# ESP32C5_RADIO register map
Vendor: Espressif; Series: ESP32-C5; File version: 0.1
Registers are 32-bit, read-write, no defined reset value unless marked. A register's access mark holds for its fields unless they carry their own. Offsets are from the block's base; [hi:lo] are bit positions; 'fields as' and 'values as' point back to an identical list.

## LP_CLKRST_RESET_CAUSE — Low-power clock/reset registers: the reset cause of the HP core. Firmware reads it after boot; the host reads it through JTAG after a power cycle.
Base 0x600B0400
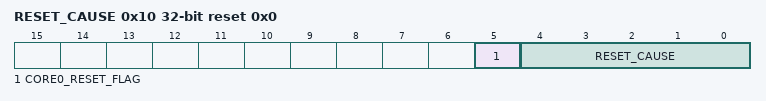
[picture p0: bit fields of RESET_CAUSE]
0x10 RESET_CAUSE ro reset 0x0 — Why the HP core last left reset. It holds until the next reset, so a host reads it through JTAG after the core returned.
  [5] CORE0_RESET_FLAG — Set when the HP core left reset.
  [4:0] RESET_CAUSE — The reset cause code: one is a power-on reset; others are system, watchdog, brown-out, USB Serial/JTAG and JTAG resets.

## USB_SERIAL_JTAG — USB Serial/JTAG controller: the CDC-ACM data FIFO, its configuration and the two interrupts of the serial endpoints. The JTAG side and the other interrupt sources are not described.
Base 0x6000F000
0x00 EP1 reset 0x0 — FIFO access for the CDC-ACM data IN and OUT endpoints: a write appends a byte to the IN FIFO, a read takes one from the OUT FIFO.
  [7:0] RDWR_BYTE — One byte of the IN or OUT FIFO.
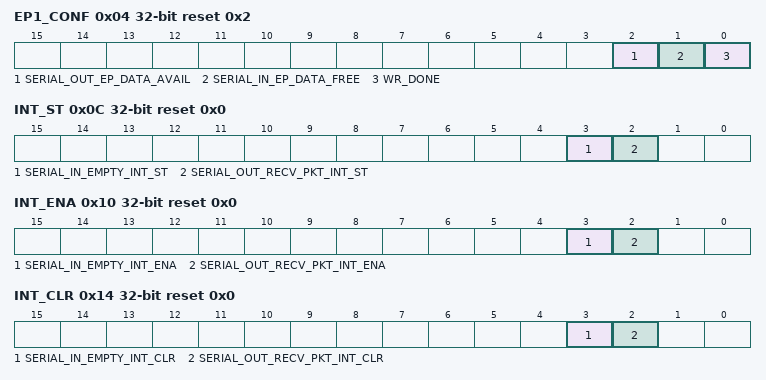
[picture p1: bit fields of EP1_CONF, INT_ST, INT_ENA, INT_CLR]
0x04 EP1_CONF reset 0x2 — Configuration and status of the CDC-ACM FIFOs.
  [2] SERIAL_OUT_EP_DATA_AVAIL ro — The OUT FIFO holds a byte to read.
  [1] SERIAL_IN_EP_DATA_FREE ro — The IN FIFO has room for a byte. After WR_DONE it stays clear until the host has read the packet.
  [0] WR_DONE wo — Writing one hands the bytes in the IN FIFO to the host as one packet; an empty FIFO sends a zero-length packet.
0x0C INT_ST ro reset 0x0 — Masked interrupt status of the serial endpoints.
  [3] SERIAL_IN_EMPTY_INT_ST — The IN endpoint became empty, and its interrupt is enabled.
  [2] SERIAL_OUT_RECV_PKT_INT_ST — The OUT endpoint received a packet, and its interrupt is enabled.
0x10 INT_ENA reset 0x0 — Interrupt enables of the serial endpoints.
  [3] SERIAL_IN_EMPTY_INT_ENA — Enables the IN endpoint's empty interrupt.
  [2] SERIAL_OUT_RECV_PKT_INT_ENA — Enables the OUT endpoint's packet-received interrupt.
0x14 INT_CLR wo reset 0x0 — Interrupt acknowledgement of the serial endpoints: writing one clears the event.
  [3] SERIAL_IN_EMPTY_INT_CLR — Writing one clears the IN endpoint's empty event.
  [2] SERIAL_OUT_RECV_PKT_INT_CLR — Writing one clears the OUT endpoint's packet-received event.

## USB_SERIAL_JTAG_PADS — USB Serial/JTAG pad configuration: the software override of the D+ and D- pull-ups and the pad enable.
Base 0x6000F000
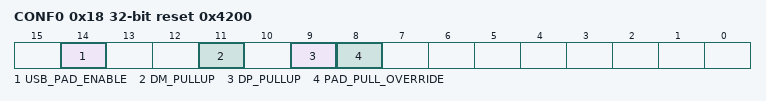
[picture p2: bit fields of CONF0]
0x18 CONF0 reset 0x4200 — PHY and pad configuration. Only the pull-up override and the pad enable are described.
  [14] USB_PAD_ENABLE — Enables the USB pad function.
  [11] DM_PULLUP — D- pull-up, while PAD_PULL_OVERRIDE is set.
  [9] DP_PULLUP — D+ pull-up, while PAD_PULL_OVERRIDE is set.
  [8] PAD_PULL_OVERRIDE — Software controls the D+ and D- pull-ups and pull-downs.

## WIFI_MAC_AUX_TSF_CONTROL — SoftAP, NAN and broadcast-TWT TSF control words. Complete public leaves prove their addresses and exact enable/mode masks; unrelated bits and hardware transition rules remain unnamed.
Base 0x600AD860
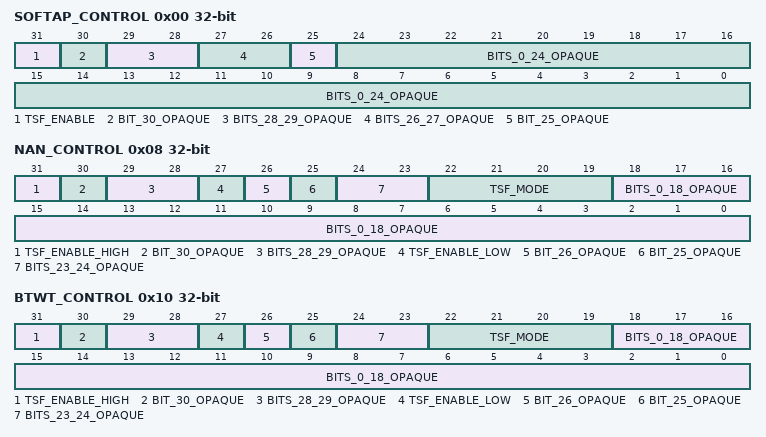
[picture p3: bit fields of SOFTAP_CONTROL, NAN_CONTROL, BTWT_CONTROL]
0x00 SOFTAP_CONTROL — Project-assigned name. Complete hal_disable_softap_tsf clears bits 31:30. Generic TSF enable/disable leaves independently identify bit 31 as the domain enable; bit 30 remains unknown.
  [31] TSF_ENABLE — Project-assigned name.
  [30] BIT_30_OPAQUE — Opaque: meaning not established.
  [29:28] BITS_28_29_OPAQUE — Opaque: meaning not established. Observed source use; the individual hardware meaning is unknown.
  [27:26] BITS_26_27_OPAQUE — Opaque: meaning not established. Observed source use; the individual hardware meaning is unknown.
  [25] BIT_25_OPAQUE — Opaque: meaning not established. Observed source use; the individual hardware meaning is unknown.
  [24:0] BITS_0_24_OPAQUE — Opaque: meaning not established. Observed source use; the individual hardware meaning is unknown.
0x08 NAN_CONTROL — Project-assigned name. Complete NAN enable/disable leaves use the same two-stage gate and mode transaction as station TSF at this distinct word.
  [31] TSF_ENABLE_HIGH — Project-assigned name.
  [30] BIT_30_OPAQUE — Opaque: meaning not established. Observed source use; the individual hardware meaning is unknown.
  [29:28] BITS_28_29_OPAQUE — Opaque: meaning not established. Observed source use; the individual hardware meaning is unknown.
  [27] TSF_ENABLE_LOW — Project-assigned name.
  [26] BIT_26_OPAQUE — Opaque: meaning not established. Observed source use; the individual hardware meaning is unknown.
  [25] BIT_25_OPAQUE — Opaque: meaning not established. Observed source use; the individual hardware meaning is unknown.
  [24:23] BITS_23_24_OPAQUE — Opaque: meaning not established. Observed source use; the individual hardware meaning is unknown.
  [22:19] TSF_MODE — Project-assigned name.
  [18:0] BITS_0_18_OPAQUE — Opaque: meaning not established. Observed source use; the individual hardware meaning is unknown.
0x10 BTWT_CONTROL — Project-assigned name. Complete hal_enable_sta_btwt_tsf enables or disables the broadcast-TWT TSF domain using the same gate and mode masks as station TSF.
  fields as NAN_CONTROL
